# PRU_ICSSG0_PR1_ICSS_ECAP0_ECAP_SLV_local register map
Vendor: Texas Instruments
Peripheral module from a debugger description file (folder am65x).
Registers are 32-bit, read-write, reset 0x0 unless marked. A register's access mark holds for its fields unless they carry their own. Offsets are as the file gives them; lines under a group give offsets from that group; [hi:lo] are bit positions; {n}, {i} and the like mark numbered series; 'fields as' and 'values as' point back to an identical list; <NAME> marks a mode.

## PRU_ICSSG0_PR1_ICSS_ECAP0_ECAP_SLV
0x00 ECAP_TSCNT — Time Stamp Counter Register.
  [31:0] TSCNT — Active 32-bit counter register which is used as the capture time-base.
0x04 ECAP_CNTPHS — Counter Phase Control Register.
  [31:0] CNTPHS — Counter phase value register that can be programmed for phase lag/lead. This register shadowsECAP_TSCNT and is loaded into ECAP_TSCNT upon either a SYNCI event or software force via a control bit. Used to achieve phase control synchronization with respect to other ECAP and EPWM time-bases.
0x08 ECAP_CAP1 — Capture-1 Register.
  [31:0] CAP1 — This register can be loaded (written) by the following: a) Time-stamp (that is, counter value) during a capture event. b) Software may be useful for test purposes/initialisation. c) APRD shadow register (that is, ECAP_CAP3) when used in APWM mode.
0x0C ECAP_CAP2 — Capture-2 Register.
  [31:0] CAP2 — This register can be loaded (written) by the following: a) Time-stamp (that is, counter value) during a capture event. b) Software may be useful for test purposes. c) ACMP shadow register (that is, ECAP_CAP4) when used in APWM mode.
0x10 ECAP_CAP3 — Capture-3 Register.
  [31:0] CAP3 — In CMP mode this is a time-stamp capture register. In APWM mode this is the period shadow (APER) register. User updates the PWM period value via this register. In this modeECAP_CAP3 (APRD) shadows ECAP_CAP1.
0x14 ECAP_CAP4 — Capture-4 Register.
  [31:0] CAP4 — In CMP mode this is a time-stamp capture register. In APWM mode this is the compare shadow (ACMP) register. User updates the PWM compare value via this register. In this modeECAP_CAP4 (ACMP) shadows ECAP_CAP2.
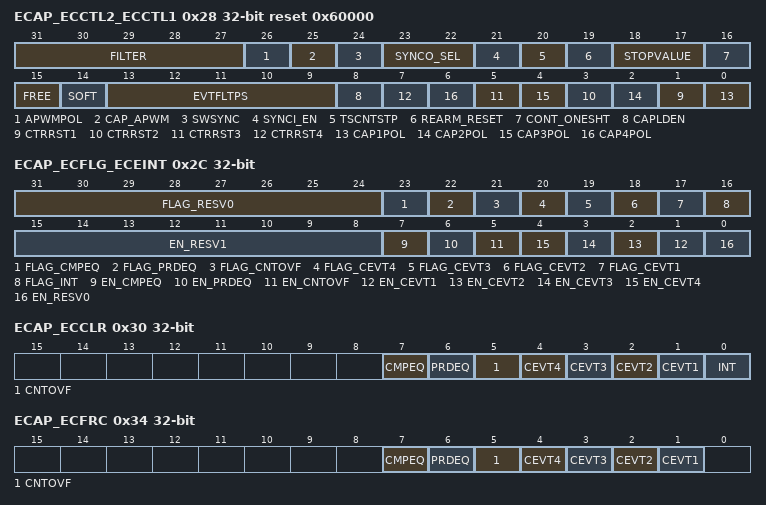
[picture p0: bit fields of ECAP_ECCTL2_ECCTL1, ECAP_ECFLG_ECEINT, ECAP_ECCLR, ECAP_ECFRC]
0x28 ECAP_ECCTL2_ECCTL1 access per field reset 0x60000 — ECAP Control Register 1.
  [31:27] FILTER ro
  [26] APWMPOL rw — APWM output polarity select: 0h = Output is active high (that is, compare value defines high time) 1h = Output is active low (that is, compare value defines low time) Note: This is applicable only in APWM operating mode.
  [25] CAP_APWM rw — CAP/APWM operating mode select: 0h = ECAP module operates in capture mode. This mode forces the following configuration: a) Inhibits b) Inhibits shadow loads on c) Permits user to enable d) ECAP input/APWM output pin operates as a capture input. 1h = ECAP module operates in APWM mode. This mode forces the following configuration: a) Resets TSCNT on CTR = PRD event (period boundary). b) Permits shadow loading on c) Disables loading of time-stamps into d) ECAP input/APWM ouput pin operates as a APWM output.
  [24] SWSYNC rw — Software forced counter ( 0h = Writing a zero has no effect will always return a zero 1h = Writing a one will force a Note: This provides a convenient software method to synchronize some or all ECAP timebases. In APWM mode, the synchronizing can also be done via the CTR = PRD event.
  [23:22] SYNCO_SEL rw — Sync-out select: 0h = Select sync-in event to be the sync-out signal (pass through) 1h = Select CTR = PRD event to be the sync-out signal 2h = Disable sync out signal 3h = Disable sync out signal Note: Selection CTR = PRD is meaningful only in APWM mode, however can still be chosen in CAP mode, if user believes it to be useful.
  [21] SYNCI_EN rw — Counter ( 0h = Disable sync-in option 1h = Enable counter (
  [20] TSCNTSTP rw — Counter stop (freeze) control: 0h = Counter stopped 1h = Counter free running
  [19] REARM_RESET rw — One-shot re-arming, that is, wait for stop trigger: 0h = Writing a zero has no effect (reading always returns a 0) 1h = Writing a one arms the one-shot sequence as follows: 1) resets the mod4 counter to zero 2) un-freezes the mod4 counter 3) enables capture register loads Note: The re-arm function is valid in onesht or continous mode.
  [18:17] STOPVALUE rw — Stop value for one-shot mode. This is the number (between 1-4) of captures allowed to occur before the CAP(1-4) registers are frozen, that is, capture sequence is stopped. 0h = Stop after capture event 1 1h = Stop after capture event 2 2h = Stop after capture event 3 3h = Stop after capture event 4 Note: STOPVALUE is compared to mod4 counter, and when equal, the following two actions occur: (1) Mod4 counter is stopped (frozen). (2) Capture register loads are inhibited. Note: In one shot mode, further interrupt events are blocked until re-armed, once the number of events captured has been reached .
  [16] CONT_ONESHT rw — Continuous or one-shot mode control (applicable only in capture mode): 0h = Operate in continuous mode 1h = Operate in one-shot mode
  [15] FREE rw — Emulation control. 0h = 1h = 0b1x =
  [14] SOFT rw — Emulation control. 0h = 1h = 0b1x =
  [13:9] EVTFLTPS rw — Event filter prescale select: 0h = Divide by 1 (that is, no prescale, by-pass the prescaler) 1h = Divide by 2 2h = Divide by 4 3h = Divide by 6 4h = Divide by 8 5h = Divide by 10 1Eh = Divide by 60 1Fh = Divide by 62
  [8] CAPLDEN rw — Enable loading of CAP(1-4) registers on a capture event: 0h = Disable CAP (1-4) register loads at capture event time 1h = Enable CAP(1-4) register loads at capture event time
  [2n-1] CTRRST{n} rw (n=1..4) — Counter reset on capture event {n}: 0h = Do not reset counter on capture event {n} (absolute time stamp) 1h = Reset counter after event {n} time-stamp has been captured (used in difference mode operation)
  [2n-2] CAP{n}POL rw (n=1..4) — Capture event {n} polarity select: 0h = Capture event {n} triggered on a rising edge (RE) 1h = Capture event {n} triggered on a falling edge (FE)
0x2C ECAP_ECFLG_ECEINT access per field — ECAP Interrupt Enable Register.
  [31:24] FLAG_RESV0 ro
  [23] FLAG_CMPEQ ro — Compare equal status flag: 0h = Indicates no event occurred 1h = Indicates the counter ( Note: This flag is only active in APWM mode.
  [22] FLAG_PRDEQ ro — Period equal status flag: 0h = Indicates no event occurred 1h = Indicates the counter ( Note: This flag is only active in APWM mode.
  [21] FLAG_CNTOVF ro — Counter overflow status flag: 0h = Indicates no event occurred 1h = Indicates the counter ( Note: This flag is active in CAP and APWM mode.
  [20] FLAG_CEVT4 ro — Capture event 4 status flag: 0h = Indicates no event occurred 1h = Indicates the fourth event occurred at ECAPx pin Note: This flag is only active in CAP mode.
  [19] FLAG_CEVT3 ro — Capture event 3 status flag: 0h = Indicates no event occurred 1h = Indicates the third event occurred at ECAPx pin Note: This flag is only active in CAP mode.
  [18] FLAG_CEVT2 ro — Capture event 2 status flag: 0h = Indicates no event occurred 1h = Indicates the second event occurred at ECAPx pin Note: This flag is only active in CAP mode.
  [17] FLAG_CEVT1 ro — Capture event 1 status flag: 0h = Indicates no event occurred 1h = Indicates the first event occurred at ECAPx pin Note: This flag is only active in CAP mode.
  [16] FLAG_INT ro — Global interrupt status flag: 0h = Indicates no interrupt generated 1h = Indicates that an interrupt was generated from one of the following events
  [15:8] EN_RESV1 ro
  [7] EN_CMPEQ rw — Compare equal interrupt enable: 0h = Disable compare equal as an interrupt source 1h = Enable compare equal as an interrupt source
  [6] EN_PRDEQ rw — Period equal interrupt enable: 0h = Disable period equal as an interrupt source 1h = Enable period equal as an interrupt source
  [5] EN_CNTOVF rw — Counter overflow interrupt enable: 0h = Disable counter overflow as an interrupt source 1h = Enable counter overflow as an interrupt source
  [n] EN_CEVT{n} rw (n=1..4) — Capture event {n} interrupt enable: 0h = Disable capture event 1 as an interrupt source 1h = Enable capture event 1 as an interrupt source
  [0] EN_RESV0 ro
0x30 ECAP_ECCLR access per field — ECAP Interrupt Clear Register.
  [7] CMPEQ rw — Compare equal status flag: 0h = Writing a 0 has no effect. Always reads back a 0. 1h = Writing a 1 clears the status flag condition
  [6] PRDEQ rw — Period equal status flag: 0h = Writing a 0 has no effect. Always reads back a 0. 1h = Writing a 1 clears the status flag condition
  [5] CNTOVF rw — Counter overflow status flag: 0h = Writing a 0 has no effect. Always reads back a 0. 1h = Writing a 1 clears the status flag condition
  [n] CEVT{n} rw (n=1..4) — Capture event {n} status flag: 0h = Writing a 0 has no effect. Always reads back a 0. 1h = Writing a 1 clears the status flag condition
  [0] INT rw — Global interrupt clear flag: 0h = Writing a 0 has no effect. Always reads back a 0. 1h = Writing a 1 clears the clear flag and enable further interrupts to be generated if any of the clear flags are set to 1
0x34 ECAP_ECFRC access per field — ECAP Interrupt Forcing Register.
  [7] CMPEQ rw — Force compare equal: 0h = Writing of 0 is ignored. Always reads back a 0. 1h = Writing a 1 sets the the CMPEQ flag bit
  [6] PRDEQ rw — Force period equal: 0h = Writing of 0 is ignored. Always reads back a 0. 1h = Writing a 1 sets the the PRDEQ flag bit
  [5] CNTOVF rw — Force counter overflow: 0h = Writing of 0 is ignored. Always reads back a 0. 1h = Writing a 1 sets the the CNTOVF flag bit
  [n] CEVT{n} rw (n=1..4) — Force capture event {n}: 0h = Writing of 0 is ignored. Always reads back a 0. 1h = Writing a 1 sets the the CEVT{n} flag bit
0x5C ECAP_PID ro reset 0x44D22100 — ECAP Peripheral Id Register.
  [31:0] REVID — TI internal data.
